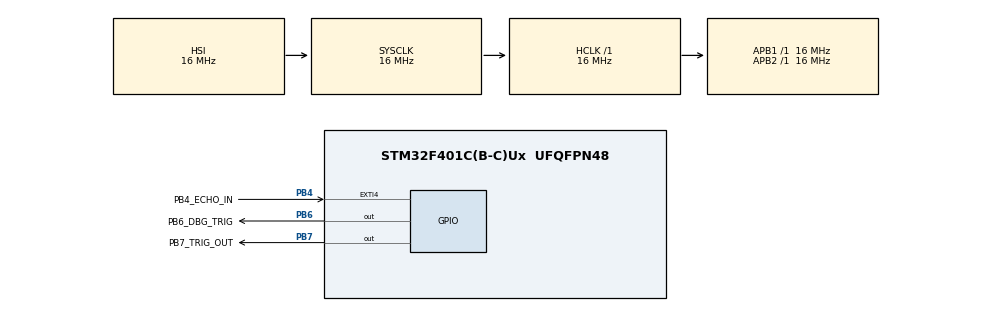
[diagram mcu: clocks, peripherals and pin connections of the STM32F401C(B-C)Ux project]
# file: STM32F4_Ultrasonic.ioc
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Mcu.Family=STM32F4
Mcu.Name=STM32F401C(B-C)Ux
Mcu.Package=UFQFPN48
NVIC.PriorityGroup=NVIC_PRIORITYGROUP_4
NVIC.TIM2_IRQn=true\:0\:0\:false\:false\:true\:true\:true\:true
NVIC.TIM5_IRQn=true\:0\:0\:false\:false\:true\:true\:true\:true
PB4.GPIO_Label=PB4_ECHO_IN
PB4.GPIO_ModeDefaultEXTI=GPIO_MODE_IT_RISING_FALLING
PB4.GPIO_PuPd=GPIO_NOPULL
PB4.Signal=GPXTI4
PB6.GPIO_Label=PB6_DBG_TRIG
PB6.GPIO_PuPd=GPIO_PULLDOWN
PB6.GPIO_Speed=GPIO_SPEED_FREQ_VERY_HIGH
PB6.Signal=GPIO_Output
PB7.GPIO_Label=PB7_TRIG_OUT
PB7.GPIO_PuPd=GPIO_PULLDOWN
PB7.GPIO_Speed=GPIO_SPEED_FREQ_VERY_HIGH
PB7.Signal=GPIO_Output
ProjectManager.HeapSize=0x400
ProjectManager.StackSize=0x800
ProjectManager.TargetToolchain=STM32CubeIDE
RCC.48MHZClocksFreq_Value=32500000
RCC.AHBFreq_Value=16000000
RCC.APB1Freq_Value=16000000
RCC.APB1TimFreq_Value=16000000
RCC.APB2Freq_Value=16000000
RCC.APB2TimFreq_Value=16000000
RCC.CortexFreq_Value=16000000
RCC.HCLKFreq_Value=16000000
RCC.HSE_VALUE=25000000
RCC.HSI_VALUE=16000000
RCC.LSE_VALUE=32768
RCC.PLLN=130
RCC.SYSCLKFreq_VALUE=16000000
RCC.VCOOutputFreq_Value=130000000
TIM2.AutoReloadPreload=TIM_AUTORELOAD_PRELOAD_ENABLE
TIM2.Period=192
TIM2.TIM_MasterOutputTrigger=TIM_TRGO_ENABLE
TIM5.AutoReloadPreload=TIM_AUTORELOAD_PRELOAD_ENABLE
TIM5.Prescaler=1599
TIM5.TIM_MasterOutputTrigger=TIM_TRGO_UPDATE
VP_TIM2_VS_ClockSourceINT.Mode=Internal
VP_TIM5_VS_ClockSourceINT.Mode=Internal
board=custom

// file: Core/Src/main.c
/* USER CODE BEGIN Header */
/**
 ******************************************************************************
 * @file           : main.c
 * @brief          : Main program body
 ******************************************************************************
 * @attention
 *
 * Copyright (c) 2024 STMicroelectronics.
 * All rights reserved.
 *
 * This software is licensed under terms that can be found in the LICENSE file
 * in the root directory of this software component.
 * If no LICENSE file comes with this software, it is provided AS-IS.
 *
 ******************************************************************************
 */
/* USER CODE END Header */
#include "main.h"

/* USER CODE BEGIN Includes */
#include "Ultrasonic_AJSR04.h"
/* USER CODE END Includes */

void SystemClock_Config(void);
static void MX_GPIO_Init(void);
static void MX_TIM2_Init(void);
static void MX_TIM5_Init(void);

/* USER CODE BEGIN 0 */

uint64_t UserTick = 0;

void PulseFunc(void);

void Reset_TIM5(void)
{
    LL_TIM_DisableCounter(TIM5);
    LL_TIM_DisableIT_UPDATE(TIM5);
    LL_TIM_SetCounter(TIM5, (uint32_t) 0x00);
    LL_TIM_EnableIT_UPDATE(TIM5);
    LL_TIM_EnableCounter(TIM5);
}

/* USER CODE END 0 */

int main(void)
{

    /* MCU Configuration--------------------------------------------------------*/

    /* Reset of all peripherals, Initializes the Flash interface and the Systick. */
    HAL_Init();

    /* Configure the system clock */
    SystemClock_Config();

    /* USER CODE BEGIN SysInit */
    HAL_Delay(500);
    /* USER CODE END SysInit */

    /* Initialize all configured peripherals */
    MX_GPIO_Init();
    MX_TIM2_Init();
    MX_TIM5_Init();
    /* USER CODE BEGIN 2 */
    AJSR04_Reset();
    float Distance;
    /* USER CODE END 2 */

    /* Infinite loop */
    /* USER CODE BEGIN WHILE */
    //HAL_Delay(500);
    while (1) {
        /* USER CODE END WHILE */

        /* USER CODE BEGIN 3 */
        AJSR04_App(&Distance);

    }
    /* USER CODE END 3 */
}

void SystemClock_Config(void)
{
    RCC_OscInitTypeDef RCC_OscInitStruct = { 0 };
    RCC_ClkInitTypeDef RCC_ClkInitStruct = { 0 };

    /** Configure the main internal regulator output voltage
     */
    __HAL_RCC_PWR_CLK_ENABLE();
    __HAL_PWR_VOLTAGESCALING_CONFIG(PWR_REGULATOR_VOLTAGE_SCALE2);

    /** Initializes the RCC Oscillators according to the specified parameters
     * in the RCC_OscInitTypeDef structure.
     */
    RCC_OscInitStruct.OscillatorType = RCC_OSCILLATORTYPE_HSI;
    RCC_OscInitStruct.HSIState = RCC_HSI_ON;
    RCC_OscInitStruct.HSICalibrationValue = RCC_HSICALIBRATION_DEFAULT;
    RCC_OscInitStruct.PLL.PLLState = RCC_PLL_NONE;
    if (HAL_RCC_OscConfig(&RCC_OscInitStruct) != HAL_OK) {
        Error_Handler();
    }

    /** Initializes the CPU, AHB and APB buses clocks
     */
    RCC_ClkInitStruct.ClockType = RCC_CLOCKTYPE_HCLK | RCC_CLOCKTYPE_SYSCLK
            | RCC_CLOCKTYPE_PCLK1 | RCC_CLOCKTYPE_PCLK2;
    RCC_ClkInitStruct.SYSCLKSource = RCC_SYSCLKSOURCE_HSI;
    RCC_ClkInitStruct.AHBCLKDivider = RCC_SYSCLK_DIV1;
    RCC_ClkInitStruct.APB1CLKDivider = RCC_HCLK_DIV1;
    RCC_ClkInitStruct.APB2CLKDivider = RCC_HCLK_DIV1;

    if (HAL_RCC_ClockConfig(&RCC_ClkInitStruct, FLASH_LATENCY_0) != HAL_OK) {
        Error_Handler();
    }
}

static void MX_TIM2_Init(void)
{

    LL_TIM_InitTypeDef TIM_InitStruct = { 0 };

    /* Peripheral clock enable */
    LL_APB1_GRP1_EnableClock(LL_APB1_GRP1_PERIPH_TIM2);

    /* TIM2 interrupt Init */
    NVIC_SetPriority(TIM2_IRQn,
            NVIC_EncodePriority(NVIC_GetPriorityGrouping(), 0, 0));
    NVIC_EnableIRQ(TIM2_IRQn);

    TIM_InitStruct.Prescaler = 0;
    TIM_InitStruct.CounterMode = LL_TIM_COUNTERMODE_UP;
    TIM_InitStruct.Autoreload = 192;
    TIM_InitStruct.ClockDivision = LL_TIM_CLOCKDIVISION_DIV1;
    LL_TIM_Init(TIM2, &TIM_InitStruct);
    LL_TIM_EnableARRPreload(TIM2);
    LL_TIM_SetClockSource(TIM2, LL_TIM_CLOCKSOURCE_INTERNAL);
    LL_TIM_SetTriggerOutput(TIM2, LL_TIM_TRGO_ENABLE);
    LL_TIM_DisableMasterSlaveMode(TIM2);
    /* USER CODE BEGIN TIM2_Init 2 */
    LL_TIM_DisableIT_UPDATE(TIM2);

    /* USER CODE END TIM2_Init 2 */

}

static void MX_TIM5_Init(void)
{

    LL_TIM_InitTypeDef TIM_InitStruct = { 0 };

    /* Peripheral clock enable */
    LL_APB1_GRP1_EnableClock(LL_APB1_GRP1_PERIPH_TIM5);

    /* TIM5 interrupt Init */
    NVIC_SetPriority(TIM5_IRQn,
            NVIC_EncodePriority(NVIC_GetPriorityGrouping(), 0, 0));
    NVIC_EnableIRQ(TIM5_IRQn);

    TIM_InitStruct.Prescaler = 1599;
    TIM_InitStruct.CounterMode = LL_TIM_COUNTERMODE_UP;
    TIM_InitStruct.Autoreload = 4294967295;
    TIM_InitStruct.ClockDivision = LL_TIM_CLOCKDIVISION_DIV1;
    LL_TIM_Init(TIM5, &TIM_InitStruct);
    LL_TIM_EnableARRPreload(TIM5);
    LL_TIM_SetClockSource(TIM5, LL_TIM_CLOCKSOURCE_INTERNAL);
    LL_TIM_SetTriggerOutput(TIM5, LL_TIM_TRGO_UPDATE);
    LL_TIM_DisableMasterSlaveMode(TIM5);
    /* USER CODE BEGIN TIM5_Init 2 */
    LL_TIM_EnableIT_UPDATE(TIM5);
    LL_TIM_EnableCounter(TIM5);
    /* USER CODE END TIM5_Init 2 */

}

static void MX_GPIO_Init(void)
{
    LL_EXTI_InitTypeDef EXTI_InitStruct = { 0 };
    LL_GPIO_InitTypeDef GPIO_InitStruct = { 0 };

    /* GPIO Ports Clock Enable */
    LL_AHB1_GRP1_EnableClock(LL_AHB1_GRP1_PERIPH_GPIOB);

    /**/
    LL_GPIO_ResetOutputPin(GPIOB, PB6_DBG_TRIG_Pin | PB7_TRIG_OUT_Pin);

    /**/
    LL_SYSCFG_SetEXTISource(LL_SYSCFG_EXTI_PORTB, LL_SYSCFG_EXTI_LINE4);

    /**/
    EXTI_InitStruct.Line_0_31 = LL_EXTI_LINE_4;
    EXTI_InitStruct.LineCommand = ENABLE;
    EXTI_InitStruct.Mode = LL_EXTI_MODE_IT;
    EXTI_InitStruct.Trigger = LL_EXTI_TRIGGER_RISING_FALLING;
    LL_EXTI_Init(&EXTI_InitStruct);

    /**/
    LL_GPIO_SetPinPull(PB4_ECHO_IN_GPIO_Port, PB4_ECHO_IN_Pin, LL_GPIO_PULL_NO);

    /**/
    LL_GPIO_SetPinMode(PB4_ECHO_IN_GPIO_Port, PB4_ECHO_IN_Pin,
            LL_GPIO_MODE_INPUT);

    /**/
    GPIO_InitStruct.Pin = PB6_DBG_TRIG_Pin | PB7_TRIG_OUT_Pin;
    GPIO_InitStruct.Mode = LL_GPIO_MODE_OUTPUT;
    GPIO_InitStruct.Speed = LL_GPIO_SPEED_FREQ_VERY_HIGH;
    GPIO_InitStruct.OutputType = LL_GPIO_OUTPUT_PUSHPULL;
    GPIO_InitStruct.Pull = LL_GPIO_PULL_DOWN;
    LL_GPIO_Init(GPIOB, &GPIO_InitStruct);

    /* USER CODE BEGIN MX_GPIO_Init_2 */
//    __disable_irq();
//    HAL_Delay(500);
//    __enable_irq();

    /* EXTI interrupt init*/
    NVIC_SetPriority(EXTI4_IRQn,
            NVIC_EncodePriority(NVIC_GetPriorityGrouping(), 0, 0));
    NVIC_EnableIRQ(EXTI4_IRQn);
    /* USER CODE END MX_GPIO_Init_2 */
}

void Error_Handler(void)
{
    __disable_irq();
    while (1) {
    }
}
